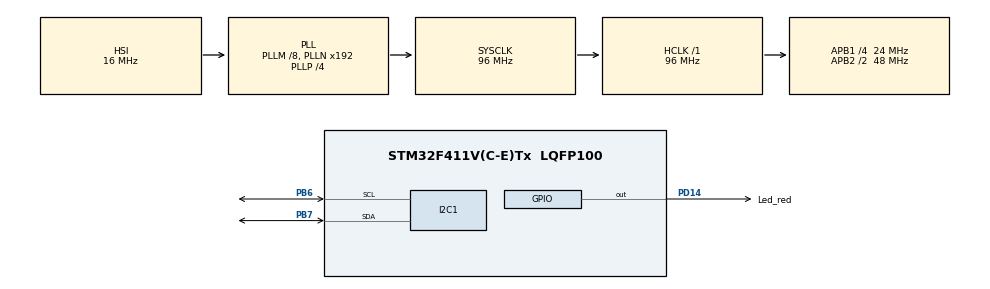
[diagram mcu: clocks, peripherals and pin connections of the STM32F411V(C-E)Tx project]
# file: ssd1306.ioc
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Mcu.Family=STM32F4
Mcu.Name=STM32F411V(C-E)Tx
Mcu.Package=LQFP100
NVIC.PriorityGroup=NVIC_PRIORITYGROUP_0
PB6.Mode=I2C
PB6.Signal=I2C1_SCL
PB7.Mode=I2C
PB7.Signal=I2C1_SDA
PD14.GPIO_Label=Led_red
PD14.Signal=GPIO_Output
ProjectManager.HeapSize=0x400
ProjectManager.StackSize=0x200
ProjectManager.TargetToolchain=Makefile
RCC.48MHZClocksFreq_Value=48000000
RCC.AHBFreq_Value=96000000
RCC.APB1CLKDivider=RCC_HCLK_DIV4
RCC.APB1Freq_Value=24000000
RCC.APB1TimFreq_Value=48000000
RCC.APB2CLKDivider=RCC_HCLK_DIV2
RCC.APB2Freq_Value=48000000
RCC.APB2TimFreq_Value=96000000
RCC.CortexFreq_Value=96000000
RCC.HCLKFreq_Value=96000000
RCC.HSE_VALUE=8000000
RCC.HSI_VALUE=16000000
RCC.LSE_VALUE=32768
RCC.PLLI2SM=5
RCC.PLLI2SN=200
RCC.PLLM=8
RCC.PLLP=RCC_PLLP_DIV4
RCC.PLLQ=8
RCC.SYSCLKFreq_VALUE=96000000
RCC.SYSCLKSource=RCC_SYSCLKSOURCE_PLLCLK
RCC.VCOOutputFreq_Value=384000000
board=STM32F411E-DISCO

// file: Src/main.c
/* USER CODE BEGIN Header */
/**
  ******************************************************************************
  * @file           : main.c
  * @brief          : Main program body
  ******************************************************************************
  * @attention
  *
  * <h2><center>&copy; Copyright (c) 2020 STMicroelectronics.
  * All rights reserved.</center></h2>
  *
  * This software component is licensed by ST under BSD 3-Clause license,
  * the "License"; You may not use this file except in compliance with the
  * License. You may obtain a copy of the License at:
  *                        opensource.org/licenses/BSD-3-Clause
  *
  ******************************************************************************
  */
/* USER CODE END Header */
#include "main.h"

/* USER CODE BEGIN Includes */

#include "ssd1306.h"
#include "fonts.h"

/* USER CODE END Includes */

I2C_HandleTypeDef hi2c1;

void SystemClock_Config(void);
static void MX_GPIO_Init(void);
static void MX_I2C1_Init(void);

int main(void)
{

  /* MCU Configuration--------------------------------------------------------*/

  /* Reset of all peripherals, Initializes the Flash interface and the Systick. */
  HAL_Init();

  /* Configure the system clock */
  SystemClock_Config();

  /* Initialize all configured peripherals */
  MX_GPIO_Init();
  MX_I2C1_Init();
  /* USER CODE BEGIN 2 */

  // Init lcd using one of the stm32HAL i2c typedefs
  if (ssd1306_Init(&hi2c1) != 0) {
    Error_Handler();
  }
  HAL_Delay(1000);

  ssd1306_Fill(Black);
  ssd1306_UpdateScreen(&hi2c1);

  HAL_Delay(1000);

  // Write data to local screenbuffer
  ssd1306_SetCursor(0, 0);
  ssd1306_WriteString("ssd1306", Font_11x18, White);

  ssd1306_SetCursor(0, 36);
  ssd1306_WriteString("4ilo", Font_11x18, White);

  // Draw rectangle on screen
  for (uint8_t i=0; i<28; i++) {
      for (uint8_t j=0; j<64; j++) {
          ssd1306_DrawPixel(100+i, 0+j, White);
      }
  }

  // Copy all data from local screenbuffer to the screen
  ssd1306_UpdateScreen(&hi2c1);

  /* USER CODE END 2 */

  /* Infinite loop */
  while (1)
  {

  }
}

void SystemClock_Config(void)
{
  RCC_OscInitTypeDef RCC_OscInitStruct = {0};
  RCC_ClkInitTypeDef RCC_ClkInitStruct = {0};

  /** Configure the main internal regulator output voltage
  */
  __HAL_RCC_PWR_CLK_ENABLE();
  __HAL_PWR_VOLTAGESCALING_CONFIG(PWR_REGULATOR_VOLTAGE_SCALE1);
  /** Initializes the RCC Oscillators according to the specified parameters
  * in the RCC_OscInitTypeDef structure.
  */
  RCC_OscInitStruct.OscillatorType = RCC_OSCILLATORTYPE_HSI;
  RCC_OscInitStruct.HSIState = RCC_HSI_ON;
  RCC_OscInitStruct.HSICalibrationValue = RCC_HSICALIBRATION_DEFAULT;
  RCC_OscInitStruct.PLL.PLLState = RCC_PLL_ON;
  RCC_OscInitStruct.PLL.PLLSource = RCC_PLLSOURCE_HSI;
  RCC_OscInitStruct.PLL.PLLM = 8;
  RCC_OscInitStruct.PLL.PLLN = 192;
  RCC_OscInitStruct.PLL.PLLP = RCC_PLLP_DIV4;
  RCC_OscInitStruct.PLL.PLLQ = 8;
  if (HAL_RCC_OscConfig(&RCC_OscInitStruct) != HAL_OK)
  {
    Error_Handler();
  }
  /** Initializes the CPU, AHB and APB buses clocks
  */
  RCC_ClkInitStruct.ClockType = RCC_CLOCKTYPE_HCLK|RCC_CLOCKTYPE_SYSCLK
                              |RCC_CLOCKTYPE_PCLK1|RCC_CLOCKTYPE_PCLK2;
  RCC_ClkInitStruct.SYSCLKSource = RCC_SYSCLKSOURCE_PLLCLK;
  RCC_ClkInitStruct.AHBCLKDivider = RCC_SYSCLK_DIV1;
  RCC_ClkInitStruct.APB1CLKDivider = RCC_HCLK_DIV4;
  RCC_ClkInitStruct.APB2CLKDivider = RCC_HCLK_DIV2;

  if (HAL_RCC_ClockConfig(&RCC_ClkInitStruct, FLASH_LATENCY_3) != HAL_OK)
  {
    Error_Handler();
  }
}

static void MX_I2C1_Init(void)
{

  hi2c1.Instance = I2C1;
  hi2c1.Init.ClockSpeed = 100000;
  hi2c1.Init.DutyCycle = I2C_DUTYCYCLE_2;
  hi2c1.Init.OwnAddress1 = 0;
  hi2c1.Init.AddressingMode = I2C_ADDRESSINGMODE_7BIT;
  hi2c1.Init.DualAddressMode = I2C_DUALADDRESS_DISABLE;
  hi2c1.Init.OwnAddress2 = 0;
  hi2c1.Init.GeneralCallMode = I2C_GENERALCALL_DISABLE;
  hi2c1.Init.NoStretchMode = I2C_NOSTRETCH_DISABLE;
  if (HAL_I2C_Init(&hi2c1) != HAL_OK)
  {
    Error_Handler();
  }

}

static void MX_GPIO_Init(void)
{
  GPIO_InitTypeDef GPIO_InitStruct = {0};

  /* GPIO Ports Clock Enable */
  __HAL_RCC_GPIOD_CLK_ENABLE();
  __HAL_RCC_GPIOB_CLK_ENABLE();

  /*Configure GPIO pin Output Level */
  HAL_GPIO_WritePin(Led_red_GPIO_Port, Led_red_Pin, GPIO_PIN_RESET);

  /*Configure GPIO pin : Led_red_Pin */
  GPIO_InitStruct.Pin = Led_red_Pin;
  GPIO_InitStruct.Mode = GPIO_MODE_OUTPUT_PP;
  GPIO_InitStruct.Pull = GPIO_NOPULL;
  GPIO_InitStruct.Speed = GPIO_SPEED_FREQ_LOW;
  HAL_GPIO_Init(Led_red_GPIO_Port, &GPIO_InitStruct);

}

void Error_Handler(void)
{
  /* USER CODE BEGIN Error_Handler_Debug */
  /* User can add his own implementation to report the HAL error return state */
  __disable_irq();
  while (1)
  {
      HAL_GPIO_TogglePin(Led_red_GPIO_Port, Led_red_Pin);
      for (int i=0; i<10000000; i++) {
          __asm__("nop");
      }

  }
  /* USER CODE END Error_Handler_Debug */
}

/************************ (C) COPYRIGHT STMicroelectronics *****END OF FILE****/
